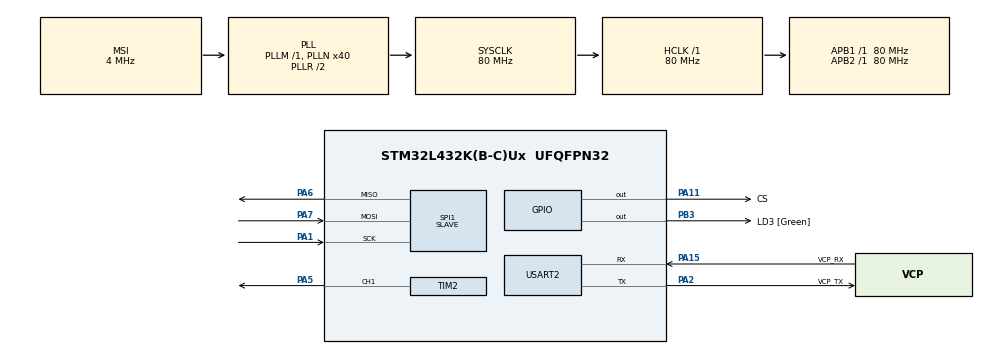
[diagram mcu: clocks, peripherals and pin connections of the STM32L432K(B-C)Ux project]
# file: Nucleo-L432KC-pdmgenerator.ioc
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Dma.Request0=SPI1_TX
Dma.SPI1_TX.0.Direction=DMA_MEMORY_TO_PERIPH
Dma.SPI1_TX.0.Instance=DMA1_Channel3
Dma.SPI1_TX.0.MemDataAlignment=DMA_MDATAALIGN_BYTE
Dma.SPI1_TX.0.MemInc=DMA_MINC_ENABLE
Dma.SPI1_TX.0.Mode=DMA_CIRCULAR
Dma.SPI1_TX.0.PeriphDataAlignment=DMA_PDATAALIGN_BYTE
Dma.SPI1_TX.0.PeriphInc=DMA_PINC_DISABLE
Dma.SPI1_TX.0.Priority=DMA_PRIORITY_LOW
Mcu.Family=STM32L4
Mcu.Name=STM32L432K(B-C)Ux
Mcu.Package=UFQFPN32
NVIC.DMA1_Channel3_IRQn=true\:0\:0\:false\:false\:true\:false
NVIC.PriorityGroup=NVIC_PRIORITYGROUP_4
PA0.GPIO_Label=MCO [High speed clock in]
PA0.Signal=RCC_CK_IN
PA1.Mode=Full_Duplex_Slave
PA1.Signal=SPI1_SCK
PA11.GPIO_Label=CS
PA11.GPIO_Speed=GPIO_SPEED_FREQ_HIGH
PA11.Signal=GPIO_Output
PA13\ (JTMS-SWDIO).GPIO_Label=SWDIO
PA13\ (JTMS-SWDIO).Signal=SYS_JTMS-SWDIO
PA14\ (JTCK-SWCLK).GPIO_Label=SWCLK
PA14\ (JTCK-SWCLK).Signal=SYS_JTCK-SWCLK
PA15\ (JTDI).GPIO_Label=VCP_RX
PA15\ (JTDI).Mode=Asynchronous
PA15\ (JTDI).Signal=USART2_RX
PA2.GPIO_Label=VCP_TX
PA2.Mode=Asynchronous
PA2.Signal=USART2_TX
PA5.Signal=S_TIM2_CH1
PA6.Mode=Full_Duplex_Slave
PA6.Signal=SPI1_MISO
PA7.Mode=Full_Duplex_Slave
PA7.Signal=SPI1_MOSI
PB3\ (JTDO-TRACESWO).GPIO_Label=LD3 [Green]
PB3\ (JTDO-TRACESWO).Signal=GPIO_Output
PC14-OSC32_IN\ (PC14).Signal=RCC_OSC32_IN
PC15-OSC32_OUT\ (PC15).Signal=RCC_OSC32_OUT
ProjectManager.HeapSize=0x200
ProjectManager.StackSize=0x400
ProjectManager.TargetToolchain=MDK-ARM V5
RCC.AHBFreq_Value=80000000
RCC.APB1Freq_Value=80000000
RCC.APB1TimFreq_Value=80000000
RCC.APB2Freq_Value=80000000
RCC.APB2TimFreq_Value=80000000
RCC.CortexFreq_Value=80000000
RCC.HCLKFreq_Value=80000000
RCC.HSE_VALUE=8000000
RCC.HSI16_VALUE=16000000
RCC.HSI48_VALUE=48000000
RCC.HSI_VALUE=16000000
RCC.LSE_VALUE=32768
RCC.MSI_VALUE=4000000
RCC.PLLMUL=RCC_PLLMUL_4
RCC.PLLN=40
RCC.SYSCLKFreq_VALUE=80000000
RCC.SYSCLKSource=RCC_SYSCLKSOURCE_PLLCLK
RCC.VCOOutputFreq_Value=160000000
SH.S_TIM2_CH1.0=TIM2_CH1,PWM Generation1 CH1
SPI1.DataSize=SPI_DATASIZE_8BIT
SPI1.Direction=SPI_DIRECTION_2LINES
SPI1.FirstBit=SPI_FIRSTBIT_LSB
SPI1.Mode=SPI_MODE_SLAVE
SPI1.VirtualType=VM_SLAVE
TIM2.Channel-PWM\ Generation1\ CH1=TIM_CHANNEL_1
TIM2.Period=9
TIM2.Prescaler=7
TIM2.Pulse-PWM\ Generation1\ CH1=5
USART2.VirtualMode-Asynchronous=VM_ASYNC
USART2.WordLength=WORDLENGTH_8B
VP_TIM2_VS_ClockSourceINT.Mode=Internal
board=NUCLEO-L432KC

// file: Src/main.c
/**
  ******************************************************************************
  * File Name          : main.c
  * Description        : Main program body
  ******************************************************************************
  ** This notice applies to any and all portions of this file
  * that are not between comment pairs USER CODE BEGIN and
  * USER CODE END. Other portions of this file, whether
  * inserted by the user or by software development tools
  * are owned by their respective copyright owners.
  *
  * COPYRIGHT(c) 2018 STMicroelectronics
  *
  * Redistribution and use in source and binary forms, with or without modification,
  * are permitted provided that the following conditions are met:
  *   1. Redistributions of source code must retain the above copyright notice,
  *      this list of conditions and the following disclaimer.
  *   2. Redistributions in binary form must reproduce the above copyright notice,
  *      this list of conditions and the following disclaimer in the documentation
  *      and/or other materials provided with the distribution.
  *   3. Neither the name of STMicroelectronics nor the names of its contributors
  *      may be used to endorse or promote products derived from this software
  *      without specific prior written permission.
  *
  * THIS SOFTWARE IS PROVIDED BY THE COPYRIGHT HOLDERS AND CONTRIBUTORS "AS IS"
  * AND ANY EXPRESS OR IMPLIED WARRANTIES, INCLUDING, BUT NOT LIMITED TO, THE
  * IMPLIED WARRANTIES OF MERCHANTABILITY AND FITNESS FOR A PARTICULAR PURPOSE ARE
  * DISCLAIMED. IN NO EVENT SHALL THE COPYRIGHT HOLDER OR CONTRIBUTORS BE LIABLE
  * FOR ANY DIRECT, INDIRECT, INCIDENTAL, SPECIAL, EXEMPLARY, OR CONSEQUENTIAL
  * DAMAGES (INCLUDING, BUT NOT LIMITED TO, PROCUREMENT OF SUBSTITUTE GOODS OR
  * SERVICES; LOSS OF USE, DATA, OR PROFITS; OR BUSINESS INTERRUPTION) HOWEVER
  * CAUSED AND ON ANY THEORY OF LIABILITY, WHETHER IN CONTRACT, STRICT LIABILITY,
  * OR TORT (INCLUDING NEGLIGENCE OR OTHERWISE) ARISING IN ANY WAY OUT OF THE USE
  * OF THIS SOFTWARE, EVEN IF ADVISED OF THE POSSIBILITY OF SUCH DAMAGE.
  *
  ******************************************************************************
  */

#include "main.h"
#include "stm32l4xx_hal.h"

/* USER CODE BEGIN Includes */

/* PDM data as generated by Octave. Each byte contains one PDM bit */
#include "tones/pdm2048kHz/tone512HzA8.h"
#define PDMBUFLEN (sizeof(pdmdata)/8)

/* Contains same PDM data but packed in uint8_t */
uint8_t pdmBuffer8[PDMBUFLEN];

/* USER CODE END Includes */

SPI_HandleTypeDef hspi1;
DMA_HandleTypeDef hdma_spi1_tx;

TIM_HandleTypeDef htim2;

UART_HandleTypeDef huart2;

/* USER CODE BEGIN PV */
/* Private variables ---------------------------------------------------------*/

/* USER CODE END PV */

void SystemClock_Config(void);
static void MX_GPIO_Init(void);
static void MX_DMA_Init(void);
static void MX_SPI1_Init(void);
static void MX_USART2_UART_Init(void);
static void MX_TIM2_Init(void);

void HAL_TIM_MspPostInit(TIM_HandleTypeDef *htim);

/* USER CODE BEGIN PFP */
/* Private function prototypes -----------------------------------------------*/

/* USER CODE END PFP */

int main(void)
{

  /* USER CODE BEGIN 1 */
	HAL_StatusTypeDef retval;
	int i;
  /* USER CODE END 1 */

  /* MCU Configuration----------------------------------------------------------*/

  /* Reset of all peripherals, Initializes the Flash interface and the Systick. */
  HAL_Init();

  /* Configure the system clock */
  SystemClock_Config();

  /* Initialize all configured peripherals */
  MX_GPIO_Init();
  MX_DMA_Init();
  MX_SPI1_Init();
  MX_USART2_UART_Init();
  MX_TIM2_Init();

  /* USER CODE BEGIN 2 */

	/* Prepare PDM buffer to be sent via SPI */
	for(i=0; i<sizeof(pdmdata); i++){
		pdmBuffer8[i>>3] |= (pdmdata[i] << (i & 7));
	}

	/* Enable SPI transmission */
	retval = HAL_SPI_Transmit_DMA(&hspi1, pdmBuffer8, sizeof(pdmBuffer8));
	if(retval != HAL_OK)
		while(1);

	/* Enable 1MHz signal to simulate SPI master clock. Just for testing purposes */
	HAL_TIM_PWM_Start(&htim2, TIM_CHANNEL_1);

  /* USER CODE END 2 */

  /* Infinite loop */
  while (1)
  {

  /* USER CODE BEGIN 3 */
		HAL_Delay(200);
  }
  /* USER CODE END 3 */

}

/** System Clock Configuration
*/
void SystemClock_Config(void)
{

  RCC_OscInitTypeDef RCC_OscInitStruct;
  RCC_ClkInitTypeDef RCC_ClkInitStruct;
  RCC_PeriphCLKInitTypeDef PeriphClkInit;

    /**Initializes the CPU, AHB and APB busses clocks
    */
  RCC_OscInitStruct.OscillatorType = RCC_OSCILLATORTYPE_MSI;
  RCC_OscInitStruct.MSIState = RCC_MSI_ON;
  RCC_OscInitStruct.MSICalibrationValue = 0;
  RCC_OscInitStruct.MSIClockRange = RCC_MSIRANGE_6;
  RCC_OscInitStruct.PLL.PLLState = RCC_PLL_ON;
  RCC_OscInitStruct.PLL.PLLSource = RCC_PLLSOURCE_MSI;
  RCC_OscInitStruct.PLL.PLLM = 1;
  RCC_OscInitStruct.PLL.PLLN = 40;
  RCC_OscInitStruct.PLL.PLLP = RCC_PLLP_DIV7;
  RCC_OscInitStruct.PLL.PLLQ = RCC_PLLQ_DIV2;
  RCC_OscInitStruct.PLL.PLLR = RCC_PLLR_DIV2;
  if (HAL_RCC_OscConfig(&RCC_OscInitStruct) != HAL_OK)
  {
    _Error_Handler(__FILE__, __LINE__);
  }

    /**Initializes the CPU, AHB and APB busses clocks
    */
  RCC_ClkInitStruct.ClockType = RCC_CLOCKTYPE_HCLK|RCC_CLOCKTYPE_SYSCLK
                              |RCC_CLOCKTYPE_PCLK1|RCC_CLOCKTYPE_PCLK2;
  RCC_ClkInitStruct.SYSCLKSource = RCC_SYSCLKSOURCE_PLLCLK;
  RCC_ClkInitStruct.AHBCLKDivider = RCC_SYSCLK_DIV1;
  RCC_ClkInitStruct.APB1CLKDivider = RCC_HCLK_DIV1;
  RCC_ClkInitStruct.APB2CLKDivider = RCC_HCLK_DIV1;

  if (HAL_RCC_ClockConfig(&RCC_ClkInitStruct, FLASH_LATENCY_4) != HAL_OK)
  {
    _Error_Handler(__FILE__, __LINE__);
  }

  PeriphClkInit.PeriphClockSelection = RCC_PERIPHCLK_USART2;
  PeriphClkInit.Usart2ClockSelection = RCC_USART2CLKSOURCE_PCLK1;
  if (HAL_RCCEx_PeriphCLKConfig(&PeriphClkInit) != HAL_OK)
  {
    _Error_Handler(__FILE__, __LINE__);
  }

    /**Configure the main internal regulator output voltage
    */
  if (HAL_PWREx_ControlVoltageScaling(PWR_REGULATOR_VOLTAGE_SCALE1) != HAL_OK)
  {
    _Error_Handler(__FILE__, __LINE__);
  }

    /**Configure the Systick interrupt time
    */
  HAL_SYSTICK_Config(HAL_RCC_GetHCLKFreq()/1000);

    /**Configure the Systick
    */
  HAL_SYSTICK_CLKSourceConfig(SYSTICK_CLKSOURCE_HCLK);

  /* SysTick_IRQn interrupt configuration */
  HAL_NVIC_SetPriority(SysTick_IRQn, 0, 0);
}

/* SPI1 init function */
static void MX_SPI1_Init(void)
{

  /* SPI1 parameter configuration*/
  hspi1.Instance = SPI1;
  hspi1.Init.Mode = SPI_MODE_SLAVE;
  hspi1.Init.Direction = SPI_DIRECTION_2LINES;
  hspi1.Init.DataSize = SPI_DATASIZE_8BIT;
  hspi1.Init.CLKPolarity = SPI_POLARITY_LOW;
  hspi1.Init.CLKPhase = SPI_PHASE_1EDGE;
  hspi1.Init.NSS = SPI_NSS_SOFT;
  hspi1.Init.FirstBit = SPI_FIRSTBIT_LSB;
  hspi1.Init.TIMode = SPI_TIMODE_DISABLE;
  hspi1.Init.CRCCalculation = SPI_CRCCALCULATION_DISABLE;
  hspi1.Init.CRCPolynomial = 7;
  hspi1.Init.CRCLength = SPI_CRC_LENGTH_DATASIZE;
  hspi1.Init.NSSPMode = SPI_NSS_PULSE_DISABLE;
  if (HAL_SPI_Init(&hspi1) != HAL_OK)
  {
    _Error_Handler(__FILE__, __LINE__);
  }

}

/* TIM2 init function */
static void MX_TIM2_Init(void)
{

  TIM_ClockConfigTypeDef sClockSourceConfig;
  TIM_MasterConfigTypeDef sMasterConfig;
  TIM_OC_InitTypeDef sConfigOC;

  htim2.Instance = TIM2;
  htim2.Init.Prescaler = 7;
  htim2.Init.CounterMode = TIM_COUNTERMODE_UP;
  htim2.Init.Period = 9;
  htim2.Init.ClockDivision = TIM_CLOCKDIVISION_DIV1;
  htim2.Init.AutoReloadPreload = TIM_AUTORELOAD_PRELOAD_DISABLE;
  if (HAL_TIM_Base_Init(&htim2) != HAL_OK)
  {
    _Error_Handler(__FILE__, __LINE__);
  }

  sClockSourceConfig.ClockSource = TIM_CLOCKSOURCE_INTERNAL;
  if (HAL_TIM_ConfigClockSource(&htim2, &sClockSourceConfig) != HAL_OK)
  {
    _Error_Handler(__FILE__, __LINE__);
  }

  if (HAL_TIM_PWM_Init(&htim2) != HAL_OK)
  {
    _Error_Handler(__FILE__, __LINE__);
  }

  sMasterConfig.MasterOutputTrigger = TIM_TRGO_RESET;
  sMasterConfig.MasterSlaveMode = TIM_MASTERSLAVEMODE_DISABLE;
  if (HAL_TIMEx_MasterConfigSynchronization(&htim2, &sMasterConfig) != HAL_OK)
  {
    _Error_Handler(__FILE__, __LINE__);
  }

  sConfigOC.OCMode = TIM_OCMODE_PWM1;
  sConfigOC.Pulse = 5;
  sConfigOC.OCPolarity = TIM_OCPOLARITY_HIGH;
  sConfigOC.OCFastMode = TIM_OCFAST_DISABLE;
  if (HAL_TIM_PWM_ConfigChannel(&htim2, &sConfigOC, TIM_CHANNEL_1) != HAL_OK)
  {
    _Error_Handler(__FILE__, __LINE__);
  }

  HAL_TIM_MspPostInit(&htim2);

}

/* USART2 init function */
static void MX_USART2_UART_Init(void)
{

  huart2.Instance = USART2;
  huart2.Init.BaudRate = 115200;
  huart2.Init.WordLength = UART_WORDLENGTH_8B;
  huart2.Init.StopBits = UART_STOPBITS_1;
  huart2.Init.Parity = UART_PARITY_NONE;
  huart2.Init.Mode = UART_MODE_TX_RX;
  huart2.Init.HwFlowCtl = UART_HWCONTROL_NONE;
  huart2.Init.OverSampling = UART_OVERSAMPLING_16;
  huart2.Init.OneBitSampling = UART_ONE_BIT_SAMPLE_DISABLE;
  huart2.AdvancedInit.AdvFeatureInit = UART_ADVFEATURE_NO_INIT;
  if (HAL_UART_Init(&huart2) != HAL_OK)
  {
    _Error_Handler(__FILE__, __LINE__);
  }

}

static void MX_DMA_Init(void)
{
  /* DMA controller clock enable */
  __HAL_RCC_DMA1_CLK_ENABLE();

  /* DMA interrupt init */
  /* DMA1_Channel3_IRQn interrupt configuration */
  HAL_NVIC_SetPriority(DMA1_Channel3_IRQn, 0, 0);
  HAL_NVIC_EnableIRQ(DMA1_Channel3_IRQn);

}

/** Configure pins as
        * Analog
        * Input
        * Output
        * EVENT_OUT
        * EXTI
*/
static void MX_GPIO_Init(void)
{

  GPIO_InitTypeDef GPIO_InitStruct;

  /* GPIO Ports Clock Enable */
  __HAL_RCC_GPIOC_CLK_ENABLE();
  __HAL_RCC_GPIOA_CLK_ENABLE();
  __HAL_RCC_GPIOB_CLK_ENABLE();

  /*Configure GPIO pin Output Level */
  HAL_GPIO_WritePin(CS_GPIO_Port, CS_Pin, GPIO_PIN_RESET);

  /*Configure GPIO pin Output Level */
  HAL_GPIO_WritePin(LD3_GPIO_Port, LD3_Pin, GPIO_PIN_RESET);

  /*Configure GPIO pin : CS_Pin */
  GPIO_InitStruct.Pin = CS_Pin;
  GPIO_InitStruct.Mode = GPIO_MODE_OUTPUT_PP;
  GPIO_InitStruct.Pull = GPIO_NOPULL;
  GPIO_InitStruct.Speed = GPIO_SPEED_FREQ_HIGH;
  HAL_GPIO_Init(CS_GPIO_Port, &GPIO_InitStruct);

  /*Configure GPIO pin : LD3_Pin */
  GPIO_InitStruct.Pin = LD3_Pin;
  GPIO_InitStruct.Mode = GPIO_MODE_OUTPUT_PP;
  GPIO_InitStruct.Pull = GPIO_NOPULL;
  GPIO_InitStruct.Speed = GPIO_SPEED_FREQ_LOW;
  HAL_GPIO_Init(LD3_GPIO_Port, &GPIO_InitStruct);

}

/* USER CODE BEGIN 4 */
void HAL_SPI_TxCpltCallback(SPI_HandleTypeDef *hspi)
{
	HAL_GPIO_TogglePin(LD3_GPIO_Port, LD3_Pin);
}
/* USER CODE END 4 */

void _Error_Handler(char * file, int line)
{
  while(1)
  {
  }
}

/************************ (C) COPYRIGHT STMicroelectronics *****END OF FILE****/
